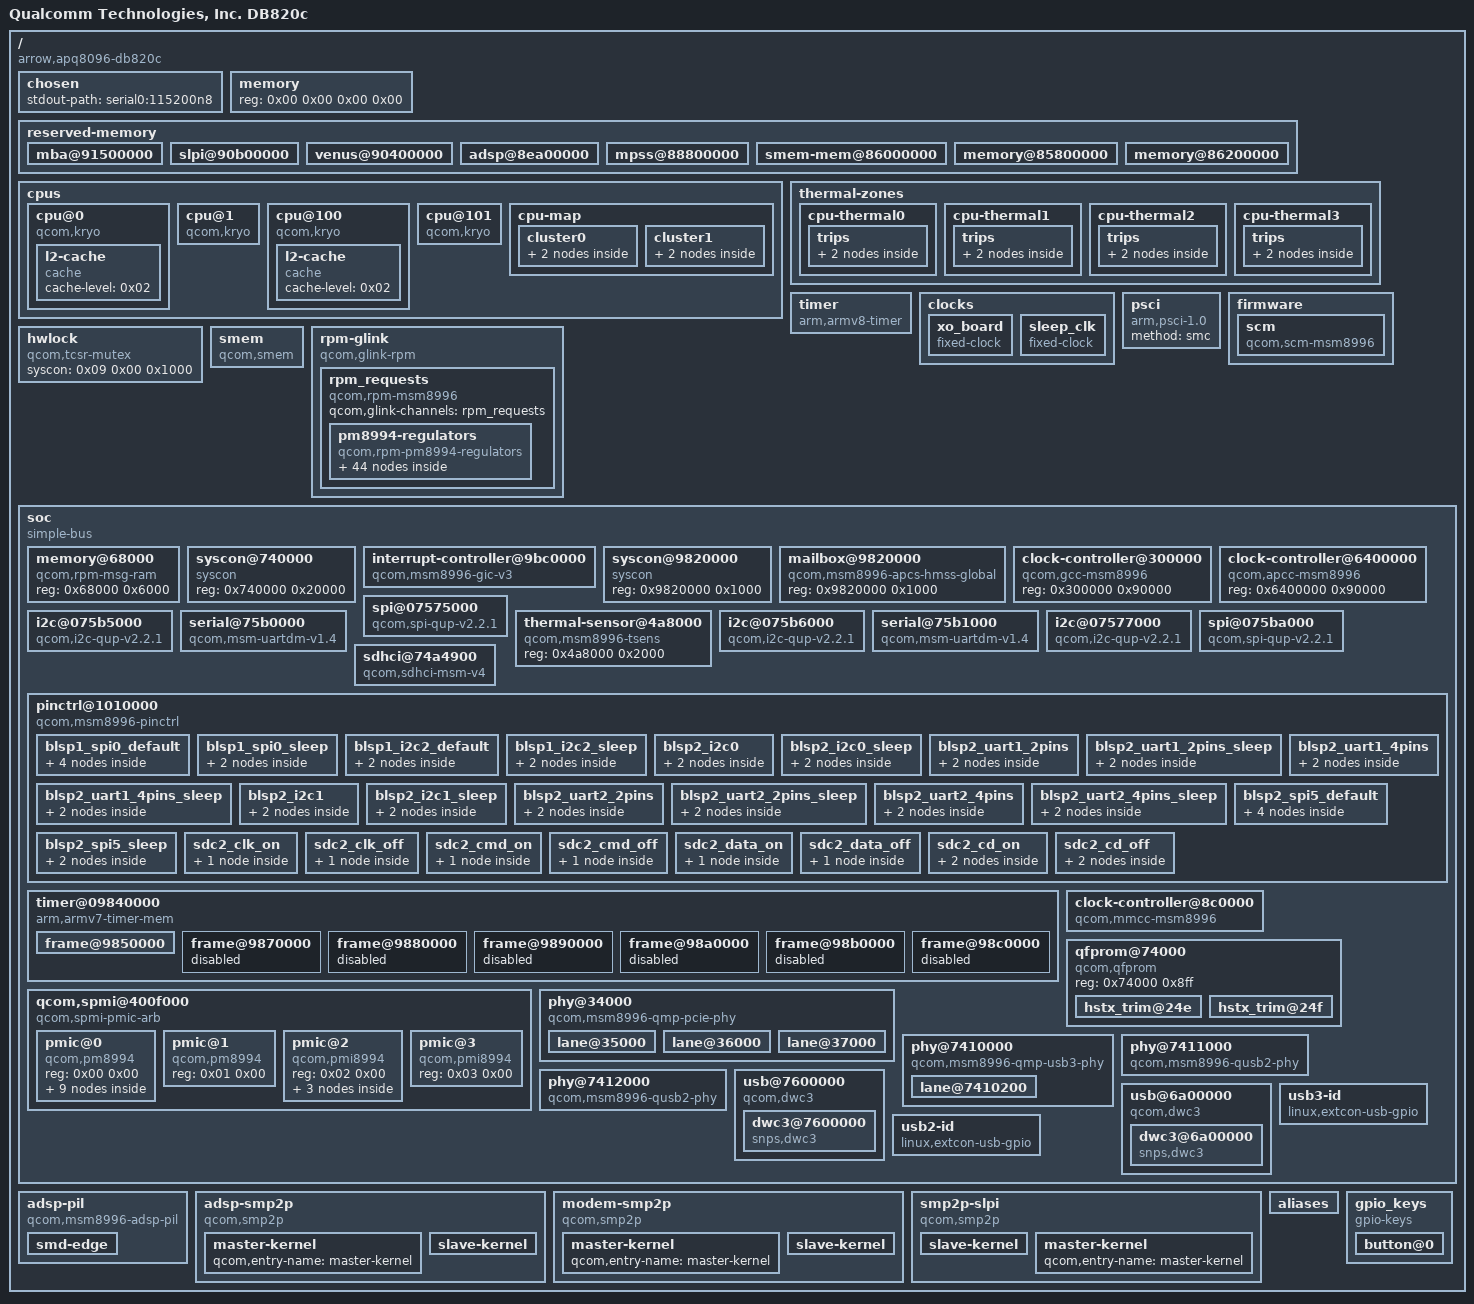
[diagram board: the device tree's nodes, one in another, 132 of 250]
/dts-v1/;

/ {
	model = "Qualcomm Technologies, Inc. DB820c";
	interrupt-parent = <0x01>;
	#address-cells = <0x02>;
	#size-cells = <0x02>;
	compatible = "arrow,apq8096-db820c\0qcom,apq8096-sbc";

	chosen {
		stdout-path = "serial0:115200n8";
	};

	memory {
		device_type = "memory";
		reg = <0x00 0x00 0x00 0x00>;
	};

	reserved-memory {
		#address-cells = <0x02>;
		#size-cells = <0x02>;
		ranges;

		mba@91500000 {
			reg = <0x00 0x91500000 0x00 0x200000>;
			no-map;
			phandle = <0x3e>;
		};

		slpi@90b00000 {
			reg = <0x00 0x90b00000 0x00 0xa00000>;
			no-map;
			phandle = <0x3f>;
		};

		venus@90400000 {
			reg = <0x00 0x90400000 0x00 0x700000>;
			no-map;
			phandle = <0x40>;
		};

		adsp@8ea00000 {
			reg = <0x00 0x8ea00000 0x00 0x1a00000>;
			no-map;
			phandle = <0x3a>;
		};

		mpss@88800000 {
			reg = <0x00 0x88800000 0x00 0x6200000>;
			no-map;
			phandle = <0x41>;
		};

		smem-mem@86000000 {
			reg = <0x00 0x86000000 0x00 0x200000>;
			no-map;
			phandle = <0x0a>;
		};

		memory@85800000 {
			reg = <0x00 0x85800000 0x00 0x800000>;
			no-map;
		};

		memory@86200000 {
			reg = <0x00 0x86200000 0x00 0x2600000>;
			no-map;
		};
	};

	cpus {
		#address-cells = <0x02>;
		#size-cells = <0x00>;

		cpu@0 {
			device_type = "cpu";
			compatible = "qcom,kryo";
			reg = <0x00 0x00>;
			enable-method = "psci";
			next-level-cache = <0x02>;
			phandle = <0x04>;

			l2-cache {
				compatible = "cache";
				cache-level = <0x02>;
				phandle = <0x02>;
			};
		};

		cpu@1 {
			device_type = "cpu";
			compatible = "qcom,kryo";
			reg = <0x00 0x01>;
			enable-method = "psci";
			next-level-cache = <0x02>;
			phandle = <0x05>;
		};

		cpu@100 {
			device_type = "cpu";
			compatible = "qcom,kryo";
			reg = <0x00 0x100>;
			enable-method = "psci";
			next-level-cache = <0x03>;
			phandle = <0x06>;

			l2-cache {
				compatible = "cache";
				cache-level = <0x02>;
				phandle = <0x03>;
			};
		};

		cpu@101 {
			device_type = "cpu";
			compatible = "qcom,kryo";
			reg = <0x00 0x101>;
			enable-method = "psci";
			next-level-cache = <0x03>;
			phandle = <0x07>;
		};

		cpu-map {

			cluster0 {

				core0 {
					cpu = <0x04>;
				};

				core1 {
					cpu = <0x05>;
				};
			};

			cluster1 {

				core0 {
					cpu = <0x06>;
				};

				core1 {
					cpu = <0x07>;
				};
			};
		};
	};

	thermal-zones {

		cpu-thermal0 {
			polling-delay-passive = <0xfa>;
			polling-delay = <0x3e8>;
			thermal-sensors = <0x08 0x03>;

			trips {

				trip0 {
					temperature = <0x124f8>;
					hysteresis = <0x7d0>;
					type = "passive";
					phandle = <0x42>;
				};

				trip1 {
					temperature = <0x1adb0>;
					hysteresis = <0x7d0>;
					type = "critical";
					phandle = <0x43>;
				};
			};
		};

		cpu-thermal1 {
			polling-delay-passive = <0xfa>;
			polling-delay = <0x3e8>;
			thermal-sensors = <0x08 0x05>;

			trips {

				trip0 {
					temperature = <0x124f8>;
					hysteresis = <0x7d0>;
					type = "passive";
					phandle = <0x44>;
				};

				trip1 {
					temperature = <0x1adb0>;
					hysteresis = <0x7d0>;
					type = "critical";
					phandle = <0x45>;
				};
			};
		};

		cpu-thermal2 {
			polling-delay-passive = <0xfa>;
			polling-delay = <0x3e8>;
			thermal-sensors = <0x08 0x08>;

			trips {

				trip0 {
					temperature = <0x124f8>;
					hysteresis = <0x7d0>;
					type = "passive";
					phandle = <0x46>;
				};

				trip1 {
					temperature = <0x1adb0>;
					hysteresis = <0x7d0>;
					type = "critical";
					phandle = <0x47>;
				};
			};
		};

		cpu-thermal3 {
			polling-delay-passive = <0xfa>;
			polling-delay = <0x3e8>;
			thermal-sensors = <0x08 0x0a>;

			trips {

				trip0 {
					temperature = <0x124f8>;
					hysteresis = <0x7d0>;
					type = "passive";
					phandle = <0x48>;
				};

				trip1 {
					temperature = <0x1adb0>;
					hysteresis = <0x7d0>;
					type = "critical";
					phandle = <0x49>;
				};
			};
		};
	};

	timer {
		compatible = "arm,armv8-timer";
		interrupts = <0x01 0x0d 0xf08 0x01 0x0e 0xf08 0x01 0x0b 0xf08 0x01 0x0a 0xf08>;
	};

	clocks {

		xo_board {
			compatible = "fixed-clock";
			#clock-cells = <0x00>;
			clock-frequency = <0x124f800>;
			clock-output-names = "xo_board";
			phandle = <0x1f>;
		};

		sleep_clk {
			compatible = "fixed-clock";
			#clock-cells = <0x00>;
			clock-frequency = <0x7ffc>;
			clock-output-names = "sleep_clk";
			phandle = <0x4a>;
		};
	};

	psci {
		compatible = "arm,psci-1.0";
		method = "smc";
	};

	firmware {

		scm {
			compatible = "qcom,scm-msm8996";
		};
	};

	hwlock {
		compatible = "qcom,tcsr-mutex";
		syscon = <0x09 0x00 0x1000>;
		#hwlock-cells = <0x01>;
		phandle = <0x0b>;
	};

	smem {
		compatible = "qcom,smem";
		memory-region = <0x0a>;
		hwlocks = <0x0b 0x03>;
	};

	rpm-glink {
		compatible = "qcom,glink-rpm";
		interrupts = <0x00 0xa8 0x01>;
		qcom,rpm-msg-ram = <0x0c>;
		mboxes = <0x0d 0x00>;

		rpm_requests {
			compatible = "qcom,rpm-msm8996";
			qcom,glink-channels = "rpm_requests";

			pm8994-regulators {
				compatible = "qcom,rpm-pm8994-regulators";
				vdd_l1-supply = <0x0e>;
				vdd_l2_l26_l28-supply = <0x0e>;
				vdd_l3_l11-supply = <0x0e>;
				vdd_l4_l27_l31-supply = <0x0e>;
				vdd_l5_l7-supply = <0x0f>;
				vdd_l14_l15-supply = <0x0f>;
				vdd_l20_l21-supply = <0x0f>;
				vdd_l25-supply = <0x0e>;

				s1 {
					phandle = <0x4b>;
				};

				s2 {
					phandle = <0x4c>;
				};

				s3 {
					regulator-min-microvolt = <0x13d620>;
					regulator-max-microvolt = <0x13d620>;
					phandle = <0x0e>;
				};

				s4 {
					regulator-min-microvolt = <0x1b7740>;
					regulator-max-microvolt = <0x1b7740>;
					phandle = <0x4d>;
				};

				s5 {
					regulator-min-microvolt = <0x20ce70>;
					regulator-max-microvolt = <0x20ce70>;
					phandle = <0x0f>;
				};

				s6 {
					phandle = <0x4e>;
				};

				s7 {
					regulator-min-microvolt = <0xc3500>;
					regulator-max-microvolt = <0xc3500>;
					phandle = <0x4f>;
				};

				s8 {
					phandle = <0x50>;
				};

				s9 {
					phandle = <0x51>;
				};

				s10 {
					phandle = <0x52>;
				};

				s11 {
					phandle = <0x53>;
				};

				s12 {
					phandle = <0x54>;
				};

				l1 {
					regulator-min-microvolt = <0xf4240>;
					regulator-max-microvolt = <0xf4240>;
					phandle = <0x55>;
				};

				l2 {
					regulator-min-microvolt = <0x1312d0>;
					regulator-max-microvolt = <0x1312d0>;
					phandle = <0x56>;
				};

				l3 {
					regulator-min-microvolt = <0xcf850>;
					regulator-max-microvolt = <0xcf850>;
					phandle = <0x57>;
				};

				l4 {
					regulator-min-microvolt = <0x12b128>;
					regulator-max-microvolt = <0x12b128>;
					phandle = <0x58>;
				};

				l5 {
					phandle = <0x59>;
				};

				l6 {
					regulator-min-microvolt = <0x124f80>;
					regulator-max-microvolt = <0x124f80>;
					phandle = <0x5a>;
				};

				l7 {
					phandle = <0x5b>;
				};

				l8 {
					regulator-min-microvolt = <0x1b7740>;
					regulator-max-microvolt = <0x1b7740>;
					phandle = <0x5c>;
				};

				l9 {
					regulator-min-microvolt = <0x1b7740>;
					regulator-max-microvolt = <0x1b7740>;
					phandle = <0x5d>;
				};

				l10 {
					regulator-min-microvolt = <0x1b7740>;
					regulator-max-microvolt = <0x1b7740>;
					phandle = <0x5e>;
				};

				l11 {
					regulator-min-microvolt = <0x118c30>;
					regulator-max-microvolt = <0x118c30>;
					phandle = <0x5f>;
				};

				l12 {
					regulator-min-microvolt = <0x1b7740>;
					regulator-max-microvolt = <0x1b7740>;
					phandle = <0x2c>;
				};

				l13 {
					regulator-min-microvolt = <0x1b7740>;
					regulator-max-microvolt = <0x2d0370>;
					phandle = <0x60>;
				};

				l14 {
					regulator-min-microvolt = <0x1b7740>;
					regulator-max-microvolt = <0x1b7740>;
					phandle = <0x61>;
				};

				l15 {
					regulator-min-microvolt = <0x1b7740>;
					regulator-max-microvolt = <0x1b7740>;
					phandle = <0x62>;
				};

				l16 {
					regulator-min-microvolt = <0x2932e0>;
					regulator-max-microvolt = <0x2932e0>;
					phandle = <0x63>;
				};

				l17 {
					regulator-min-microvolt = <0x2625a0>;
					regulator-max-microvolt = <0x2625a0>;
					phandle = <0x64>;
				};

				l18 {
					regulator-min-microvolt = <0x2932e0>;
					regulator-max-microvolt = <0x2c4020>;
					phandle = <0x65>;
				};

				l19 {
					regulator-min-microvolt = <0x2dc6c0>;
					regulator-max-microvolt = <0x2dc6c0>;
					phandle = <0x66>;
				};

				l20 {
					regulator-min-microvolt = <0x2d0370>;
					regulator-max-microvolt = <0x2d0370>;
					regulator-allow-set-load;
					phandle = <0x67>;
				};

				l21 {
					regulator-min-microvolt = <0x2d0370>;
					regulator-max-microvolt = <0x2d0370>;
					phandle = <0x68>;
				};

				l22 {
					regulator-min-microvolt = <0x325aa0>;
					regulator-max-microvolt = <0x325aa0>;
					phandle = <0x69>;
				};

				l23 {
					regulator-min-microvolt = <0x2ab980>;
					regulator-max-microvolt = <0x2ab980>;
					phandle = <0x6a>;
				};

				l24 {
					regulator-min-microvolt = <0x2eebb8>;
					regulator-max-microvolt = <0x2eebb8>;
					phandle = <0x2d>;
				};

				l25 {
					regulator-min-microvolt = <0x124f80>;
					regulator-max-microvolt = <0x124f80>;
					regulator-allow-set-load;
					phandle = <0x6b>;
				};

				l26 {
					phandle = <0x6c>;
				};

				l27 {
					regulator-min-microvolt = <0xf4240>;
					regulator-max-microvolt = <0xf4240>;
					phandle = <0x6d>;
				};

				l28 {
					regulator-min-microvolt = <0xe1d48>;
					regulator-max-microvolt = <0xe1d48>;
					regulator-allow-set-load;
					phandle = <0x2b>;
				};

				l29 {
					regulator-min-microvolt = <0x2ab980>;
					regulator-max-microvolt = <0x2ab980>;
					phandle = <0x6e>;
				};

				l30 {
					regulator-min-microvolt = <0x1b7740>;
					regulator-max-microvolt = <0x1b7740>;
					phandle = <0x6f>;
				};

				l31 {
					phandle = <0x70>;
				};

				l32 {
					regulator-min-microvolt = <0x1b7740>;
					regulator-max-microvolt = <0x1b7740>;
					phandle = <0x71>;
				};
			};
		};
	};

	soc {
		#address-cells = <0x01>;
		#size-cells = <0x01>;
		ranges = <0x00 0x00 0x00 0xffffffff>;
		compatible = "simple-bus";
		phandle = <0x72>;

		memory@68000 {
			compatible = "qcom,rpm-msg-ram";
			reg = <0x68000 0x6000>;
			phandle = <0x0c>;
		};

		syscon@740000 {
			compatible = "syscon";
			reg = <0x740000 0x20000>;
			phandle = <0x09>;
		};

		interrupt-controller@9bc0000 {
			compatible = "qcom,msm8996-gic-v3\0arm,gic-v3";
			#interrupt-cells = <0x03>;
			interrupt-controller;
			#redistributor-regions = <0x01>;
			redistributor-stride = <0x00 0x40000>;
			reg = <0x9bc0000 0x10000 0x9c00000 0x100000>;
			interrupts = <0x01 0x09 0x04>;
			phandle = <0x01>;
		};

		syscon@9820000 {
			compatible = "syscon";
			reg = <0x9820000 0x1000>;
			phandle = <0x3c>;
		};

		mailbox@9820000 {
			compatible = "qcom,msm8996-apcs-hmss-global";
			reg = <0x9820000 0x1000>;
			#mbox-cells = <0x01>;
			phandle = <0x0d>;
		};

		clock-controller@300000 {
			compatible = "qcom,gcc-msm8996";
			#clock-cells = <0x01>;
			#reset-cells = <0x01>;
			#power-domain-cells = <0x01>;
			reg = <0x300000 0x90000>;
			phandle = <0x10>;
		};

		clock-controller@6400000 {
			compatible = "qcom,apcc-msm8996";
			reg = <0x6400000 0x90000>;
			#clock-cells = <0x01>;
			phandle = <0x73>;
		};

		spi@07575000 {
			compatible = "qcom,spi-qup-v2.2.1";
			reg = <0x7575000 0x600>;
			interrupts = <0x00 0x5f 0x04>;
			clocks = <0x10 0x6f 0x10 0x6d>;
			clock-names = "core\0iface";
			pinctrl-names = "default\0sleep";
			pinctrl-0 = <0x11>;
			pinctrl-1 = <0x12>;
			#address-cells = <0x01>;
			#size-cells = <0x00>;
			status = "okay";
			label = "LS-SPI0";
			phandle = <0x74>;
		};

		i2c@075b5000 {
			compatible = "qcom,i2c-qup-v2.2.1";
			reg = <0x75b5000 0x1000>;
			interrupts = <0x00 0x65 0x00>;
			clocks = <0x10 0x81 0x10 0x84>;
			clock-names = "iface\0core";
			pinctrl-names = "default\0sleep";
			pinctrl-0 = <0x13>;
			pinctrl-1 = <0x14>;
			#address-cells = <0x01>;
			#size-cells = <0x00>;
			status = "okay";
			label = "HS-I2C2";
			phandle = <0x75>;
		};

		thermal-sensor@4a8000 {
			compatible = "qcom,msm8996-tsens";
			reg = <0x4a8000 0x2000>;
			#thermal-sensor-cells = <0x01>;
			phandle = <0x08>;
		};

		serial@75b0000 {
			compatible = "qcom,msm-uartdm-v1.4\0qcom,msm-uartdm";
			reg = <0x75b0000 0x1000>;
			interrupts = <0x00 0x72 0x04>;
			clocks = <0x10 0x88 0x10 0x81>;
			clock-names = "core\0iface";
			status = "okay";
			label = "LS-UART1";
			pinctrl-names = "default\0sleep";
			pinctrl-0 = <0x15>;
			pinctrl-1 = <0x16>;
			phandle = <0x76>;
		};

		i2c@075b6000 {
			compatible = "qcom,i2c-qup-v2.2.1";
			reg = <0x75b6000 0x1000>;
			interrupts = <0x00 0x66 0x00>;
			clocks = <0x10 0x81 0x10 0x87>;
			clock-names = "iface\0core";
			pinctrl-names = "default\0sleep";
			pinctrl-0 = <0x17>;
			pinctrl-1 = <0x18>;
			#address-cells = <0x01>;
			#size-cells = <0x00>;
			status = "okay";
			label = "LS-I2C1";
			phandle = <0x77>;
		};

		serial@75b1000 {
			compatible = "qcom,msm-uartdm-v1.4\0qcom,msm-uartdm";
			reg = <0x75b1000 0x1000>;
			interrupts = <0x00 0x73 0x04>;
			clocks = <0x10 0x8b 0x10 0x81>;
			clock-names = "core\0iface";
			status = "okay";
			label = "LS-UART0";
			pinctrl-names = "default\0sleep";
			pinctrl-0 = <0x19>;
			pinctrl-1 = <0x1a>;
			phandle = <0x78>;
		};

		i2c@07577000 {
			compatible = "qcom,i2c-qup-v2.2.1";
			reg = <0x7577000 0x1000>;
			interrupts = <0x00 0x61 0x00>;
			clocks = <0x10 0x6d 0x10 0x76>;
			clock-names = "iface\0core";
			pinctrl-names = "default\0sleep";
			pinctrl-0 = <0x1b>;
			pinctrl-1 = <0x1c>;
			#address-cells = <0x01>;
			#size-cells = <0x00>;
			status = "okay";
			label = "LS-I2C0";
			phandle = <0x79>;
		};

		spi@075ba000 {
			compatible = "qcom,spi-qup-v2.2.1";
			reg = <0x75ba000 0x600>;
			interrupts = <0x00 0x6a 0x04>;
			clocks = <0x10 0x92 0x10 0x81>;
			clock-names = "core\0iface";
			pinctrl-names = "default\0sleep";
			pinctrl-0 = <0x1d>;
			pinctrl-1 = <0x1e>;
			#address-cells = <0x01>;
			#size-cells = <0x00>;
			status = "okay";
			label = "HS-SPI1";
			phandle = <0x7a>;
		};

		sdhci@74a4900 {
			status = "okay";
			compatible = "qcom,sdhci-msm-v4";
			reg = <0x74a4900 0x314 0x74a4000 0x800>;
			reg-names = "hc_mem\0core_mem";
			interrupts = <0x00 0x7d 0x00 0x00 0xdd 0x00>;
			interrupt-names = "hc_irq\0pwr_irq";
			clock-names = "iface\0core\0xo";
			clocks = <0x10 0x68 0x10 0x67 0x1f>;
			bus-width = <0x04>;
			pinctrl-names = "default\0sleep";
			pinctrl-0 = <0x20 0x21 0x22 0x23>;
			pinctrl-1 = <0x24 0x25 0x26 0x27>;
			cd-gpios = <0x28 0x26 0x01>;
			phandle = <0x7b>;
		};

		pinctrl@1010000 {
			compatible = "qcom,msm8996-pinctrl";
			reg = <0x1010000 0x300000>;
			interrupts = <0x00 0xd0 0x04>;
			gpio-controller;
			#gpio-cells = <0x02>;
			interrupt-controller;
			#interrupt-cells = <0x02>;
			phandle = <0x28>;

			blsp1_spi0_default {
				phandle = <0x11>;

				pinmux {
					function = "blsp_spi1";
					pins = "gpio0\0gpio1\0gpio3";
				};

				pinmux_cs {
					function = "gpio";
					pins = "gpio2";
				};

				pinconf {
					pins = "gpio0\0gpio1\0gpio3";
					drive-strength = <0x0c>;
					bias-disable;
				};

				pinconf_cs {
					pins = "gpio2";
					drive-strength = <0x10>;
					bias-disable;
					output-high;
				};
			};

			blsp1_spi0_sleep {
				phandle = <0x12>;

				pinmux {
					function = "gpio";
					pins = "gpio0\0gpio1\0gpio2\0gpio3";
				};

				pinconf {
					pins = "gpio0\0gpio1\0gpio2\0gpio3";
					drive-strength = <0x02>;
					bias-pull-down;
				};
			};

			blsp1_i2c2_default {
				phandle = <0x1b>;

				pinmux {
					function = "blsp_i2c3";
					pins = "gpio47\0gpio48";
				};

				pinconf {
					pins = "gpio47\0gpio48";
					drive-strength = <0x10>;
					bias-disable = <0x00>;
				};
			};

			blsp1_i2c2_sleep {
				phandle = <0x1c>;

				pinmux {
					function = "gpio";
					pins = "gpio47\0gpio48";
				};

				pinconf {
					pins = "gpio47\0gpio48";
					drive-strength = <0x02>;
					bias-disable = <0x00>;
				};
			};

			blsp2_i2c0 {
				phandle = <0x13>;

				pinmux {
					function = "blsp_i2c7";
					pins = "gpio55\0gpio56";
				};

				pinconf {
					pins = "gpio55\0gpio56";
					drive-strength = <0x10>;
					bias-disable;
				};
			};

			blsp2_i2c0_sleep {
				phandle = <0x14>;

				pinmux {
					function = "gpio";
					pins = "gpio55\0gpio56";
				};

				pinconf {
					pins = "gpio55\0gpio56";
					drive-strength = <0x02>;
					bias-disable;
				};
			};

			blsp2_uart1_2pins {
				phandle = <0x15>;

				pinmux {
					function = "blsp_uart8";
					pins = "gpio4\0gpio5";
				};

				pinconf {
					pins = "gpio4\0gpio5";
					drive-strength = <0x10>;
					bias-disable;
				};
			};

			blsp2_uart1_2pins_sleep {
				phandle = <0x16>;

				pinmux {
					function = "gpio";
					pins = "gpio4\0gpio5";
				};

				pinconf {
					pins = "gpio4\0gpio5";
					drive-strength = <0x02>;
					bias-disable;
				};
			};

			blsp2_uart1_4pins {
				phandle = <0x7c>;

				pinmux {
					function = "blsp_uart8";
					pins = "gpio4\0gpio5\0gpio6\0gpio7";
				};

				pinconf {
					pins = "gpio4\0gpio5\0gpio6\0gpio7";
					drive-strength = <0x10>;
					bias-disable;
				};
			};

			blsp2_uart1_4pins_sleep {
				phandle = <0x7d>;

				pinmux {
					function = "gpio";
					pins = "gpio4\0gpio5\0gpio6\0gpio7";
				};

				pinconf {
					pins = "gpio4\0gpiio5\0gpio6\0gpio7";
					drive-strength = <0x02>;
					bias-disable;
				};
			};

			blsp2_i2c1 {
				phandle = <0x17>;

				pinmux {
					function = "blsp_i2c8";
					pins = "gpio6\0gpio7";
				};

				pinconf {
					pins = "gpio6\0gpio7";
					drive-strength = <0x10>;
					bias-disable;
				};
			};

			blsp2_i2c1_sleep {
				phandle = <0x18>;

				pinmux {
					function = "gpio";
					pins = "gpio6\0gpio7";
				};

				pinconf {
					pins = "gpio6\0gpio7";
					drive-strength = <0x02>;
					bias-disable;
				};
			};

			blsp2_uart2_2pins {
				phandle = <0x7e>;

				pinmux {
					function = "blsp_uart9";
					pins = "gpio49\0gpio50";
				};

				pinconf {
					pins = "gpio49\0gpio50";
					drive-strength = <0x10>;
					bias-disable;
				};
			};

			blsp2_uart2_2pins_sleep {
				phandle = <0x7f>;

				pinmux {
					function = "gpio";
					pins = "gpio49\0gpio50";
				};

				pinconf {
					pins = "gpio49\0gpio50";
					drive-strength = <0x02>;
					bias-disable;
				};
			};

			blsp2_uart2_4pins {
				phandle = <0x19>;

				pinmux {
					function = "blsp_uart9";
					pins = "gpio49\0gpio50\0gpio51\0gpio52";
				};

				pinconf {
					pins = "gpio49\0gpio50\0gpio51\0gpio52";
					drive-strength = <0x10>;
					bias-disable;
				};
			};

			blsp2_uart2_4pins_sleep {
				phandle = <0x1a>;

				pinmux {
					function = "gpio";
					pins = "gpio49\0gpio50\0gpio51\0gpio52";
				};

				pinconf {
					pins = "gpio49\0gpio50\0gpio51\0gpio52";
					drive-strength = <0x02>;
					bias-disable;
				};
			};

			blsp2_spi5_default {
				phandle = <0x1d>;

				pinmux {
					function = "blsp_spi12";
					pins = "gpio85\0gpio86\0gpio88";
				};

				pinmux_cs {
					function = "gpio";
					pins = "gpio87";
				};

				pinconf {
					pins = "gpio85\0gpio86\0gpio88";
					drive-strength = <0x0c>;
					bias-disable;
				};

				pinconf_cs {
					pins = "gpio87";
					drive-strength = <0x10>;
					bias-disable;
					output-high;
				};
			};

			blsp2_spi5_sleep {
				phandle = <0x1e>;

				pinmux {
					function = "gpio";
					pins = "gpio85\0gpio86\0gpio87\0gpio88";
				};

				pinconf {
					pins = "gpio85\0gpio86\0gpio87\0gpio88";
					drive-strength = <0x02>;
					bias-pull-down;
				};
			};

			sdc2_clk_on {
				phandle = <0x20>;

				config {
					pins = "sdc2_clk";
					bias-disable;
					drive-strength = <0x10>;
				};
			};

			sdc2_clk_off {
				phandle = <0x24>;

				config {
					pins = "sdc2_clk";
					bias-disable;
					drive-strength = <0x02>;
				};
			};

			sdc2_cmd_on {
				phandle = <0x21>;

				config {
					pins = "sdc2_cmd";
					bias-pull-up;
					drive-strength = <0x0a>;
				};
			};

			sdc2_cmd_off {
				phandle = <0x25>;

				config {
					pins = "sdc2_cmd";
					bias-pull-up;
					drive-strength = <0x02>;
				};
			};

			sdc2_data_on {
				phandle = <0x22>;

				config {
					pins = "sdc2_data";
					bias-pull-up;
					drive-strength = <0x0a>;
				};
			};

			sdc2_data_off {
				phandle = <0x26>;

				config {
					pins = "sdc2_data";
					bias-pull-up;
					drive-strength = <0x02>;
				};
			};

			sdc2_cd_on {
				phandle = <0x23>;

				mux {
					pins = "gpio38";
					function = "gpio";
				};

				config {
					pins = "gpio38";
					bias-pull-up;
					drive-strength = <0x10>;
				};
			};

			sdc2_cd_off {
				phandle = <0x27>;

				mux {
					pins = "gpio38";
					function = "gpio";
				};

				config {
					pins = "gpio38";
					bias-pull-up;
					drive-strength = <0x02>;
				};
			};
		};

		timer@09840000 {
			#address-cells = <0x01>;
			#size-cells = <0x01>;
			ranges;
			compatible = "arm,armv7-timer-mem";
			reg = <0x9840000 0x1000>;
			clock-frequency = <0x124f800>;

			frame@9850000 {
				frame-number = <0x00>;
				interrupts = <0x00 0x1f 0x04 0x00 0x1e 0x04>;
				reg = <0x9850000 0x1000 0x9860000 0x1000>;
			};

			frame@9870000 {
				frame-number = <0x01>;
				interrupts = <0x00 0x20 0x04>;
				reg = <0x9870000 0x1000>;
				status = "disabled";
			};

			frame@9880000 {
				frame-number = <0x02>;
				interrupts = <0x00 0x21 0x04>;
				reg = <0x9880000 0x1000>;
				status = "disabled";
			};

			frame@9890000 {
				frame-number = <0x03>;
				interrupts = <0x00 0x22 0x04>;
				reg = <0x9890000 0x1000>;
				status = "disabled";
			};

			frame@98a0000 {
				frame-number = <0x04>;
				interrupts = <0x00 0x23 0x04>;
				reg = <0x98a0000 0x1000>;
				status = "disabled";
			};

			frame@98b0000 {
				frame-number = <0x05>;
				interrupts = <0x00 0x24 0x04>;
				reg = <0x98b0000 0x1000>;
				status = "disabled";
			};

			frame@98c0000 {
				frame-number = <0x06>;
				interrupts = <0x00 0x25 0x04>;
				reg = <0x98c0000 0x1000>;
				status = "disabled";
			};
		};

		qcom,spmi@400f000 {
			compatible = "qcom,spmi-pmic-arb";
			reg = <0x400f000 0x1000 0x4400000 0x800000 0x4c00000 0x800000 0x5800000 0x200000 0x400a000 0x2100>;
			reg-names = "core\0chnls\0obsrvr\0intr\0cnfg";
			interrupt-names = "periph_irq";
			interrupts = <0x00 0x146 0x04>;
			qcom,ee = <0x00>;
			qcom,channel = <0x00>;
			#address-cells = <0x02>;
			#size-cells = <0x00>;
			interrupt-controller;
			#interrupt-cells = <0x04>;
			phandle = <0x80>;

			pmic@0 {
				compatible = "qcom,pm8994\0qcom,spmi-pmic";
				reg = <0x00 0x00>;
				#address-cells = <0x01>;
				#size-cells = <0x00>;

				rtc@6000 {
					compatible = "qcom,pm8941-rtc";
					reg = <0x6000 0x6100>;
					reg-names = "rtc\0alarm";
					interrupts = <0x00 0x61 0x01 0x01>;
				};

				gpios@c000 {
					compatible = "qcom,pm8994-gpio";
					reg = <0xc000>;
					gpio-controller;
					#gpio-cells = <0x02>;
					interrupts = <0x00 0xc0 0x00 0x00 0x00 0xc1 0x00 0x00 0x00 0xc2 0x00 0x00 0x00 0xc3 0x00 0x00 0x00 0xc4 0x00 0x00 0x00 0xc5 0x00 0x00 0x00 0xc6 0x00 0x00 0x00 0xc7 0x00 0x00 0x00 0xc8 0x00 0x00 0x00 0xc9 0x00 0x00 0x00 0xca 0x00 0x00 0x00 0xcb 0x00 0x00 0x00 0xcc 0x00 0x00 0x00 0xcd 0x00 0x00 0x00 0xce 0x00 0x00 0x00 0xcf 0x00 0x00 0x00 0xd0 0x00 0x00 0x00 0xd1 0x00 0x00 0x00 0xd2 0x00 0x00 0x00 0xd3 0x00 0x00 0x00 0xd4 0x00 0x00 0x00 0xd5 0x00 0x00>;
					pinctrl-names = "default";
					pinctrl-0 = <0x29>;
					phandle = <0x35>;

					pm8994_gpio5 {
						phandle = <0x29>;

						pinconf {
							pins = "gpio5";
							output-low;
							power-source = <0x02>;
						};
					};

					pm8996_gpio2 {
						phandle = <0x3d>;

						pinconf {
							pins = "gpio2";
							function = "normal";
							input-enable;
							drive-push-pull;
							bias-pull-up;
							qcom,drive-strength = <0x00>;
							power-source = <0x02>;
						};
					};

					pm8996_gpio22 {
						phandle = <0x36>;

						pinconf {
							pins = "gpio22";
							function = "normal";
							input-enable;
							bias-pull-down;
							qcom,drive-strength = <0x00>;
							power-source = <0x02>;
						};
					};
				};

				mpps@a000 {
					compatible = "qcom,pm8994-mpp";
					reg = <0xa000>;
					gpio-controller;
					#gpio-cells = <0x02>;
					interrupts = <0x00 0xa0 0x00 0x00 0x00 0xa1 0x00 0x00 0x00 0xa2 0x00 0x00 0x00 0xa3 0x00 0x00 0x00 0xa4 0x00 0x00 0x00 0xa5 0x00 0x00 0x00 0xa6 0x00 0x00 0x00 0xa7 0x00 0x00>;
					phandle = <0x81>;
				};
			};

			pmic@1 {
				compatible = "qcom,pm8994\0qcom,spmi-pmic";
				reg = <0x01 0x00>;
				#address-cells = <0x01>;
				#size-cells = <0x00>;
			};

			pmic@2 {
				compatible = "qcom,pmi8994\0qcom,spmi-pmic";
				reg = <0x02 0x00>;
				#address-cells = <0x01>;
				#size-cells = <0x00>;

				gpios@c000 {
					compatible = "qcom,pmi8994-gpio\0qcom,spmi-gpio";
					reg = <0xc000>;
					gpio-controller;
					#gpio-cells = <0x02>;
					interrupts = <0x02 0xc0 0x00 0x00 0x02 0xc1 0x00 0x00 0x02 0xc2 0x00 0x00 0x02 0xc3 0x00 0x00 0x02 0xc4 0x00 0x00 0x02 0xc5 0x00 0x00 0x02 0xc6 0x00 0x00 0x02 0xc7 0x00 0x00 0x02 0xc8 0x00 0x00 0x02 0xc9 0x00 0x00>;
					phandle = <0x37>;

					pmi8996_gpio6 {
						phandle = <0x38>;

						pinconf {
							pins = "gpio6";
							function = "normal";
							input-enable;
							bias-pull-down;
							qcom,drive-strength = <0x00>;
							power-source = <0x02>;
						};
					};
				};
			};

			pmic@3 {
				compatible = "qcom,pmi8994\0qcom,spmi-pmic";
				reg = <0x03 0x00>;
				#address-cells = <0x01>;
				#size-cells = <0x00>;
			};
		};

		clock-controller@8c0000 {
			compatible = "qcom,mmcc-msm8996";
			#clock-cells = <0x01>;
			#reset-cells = <0x01>;
			#power-domain-cells = <0x01>;
			reg = <0x8c0000 0x40000>;
			assigned-clocks = <0x2a 0x0f 0x2a 0x03 0x2a 0x07 0x2a 0x09 0x2a 0x0b>;
			assigned-clock-rates = <0x25317c00 0x30479e80 0x3a699d00 0x39387000 0x312c8040>;
			phandle = <0x2a>;
		};

		qfprom@74000 {
			compatible = "qcom,qfprom";
			reg = <0x74000 0x8ff>;
			#address-cells = <0x01>;
			#size-cells = <0x01>;

			hstx_trim@24e {
				reg = <0x24e 0x02>;
				bits = <0x05 0x04>;
				phandle = <0x2e>;
			};

			hstx_trim@24f {
				reg = <0x24f 0x01>;
				bits = <0x01 0x04>;
				phandle = <0x2f>;
			};
		};

		phy@34000 {
			compatible = "qcom,msm8996-qmp-pcie-phy";
			reg = <0x34000 0x488>;
			#clock-cells = <0x01>;
			#address-cells = <0x01>;
			#size-cells = <0x01>;
			ranges;
			clocks = <0x10 0xc0 0x10 0xbf 0x10 0xd8>;
			clock-names = "aux\0cfg_ahb\0ref";
			vdda-phy-supply = <0x2b>;
			vdda-pll-supply = <0x2c>;
			resets = <0x10 0x55 0x10 0x65 0x10 0x66>;
			reset-names = "phy\0common\0cfg";
			status = "okay";

			lane@35000 {
				reg = <0x35000 0x130 0x35200 0x200 0x35400 0x1dc>;
				#phy-cells = <0x00>;
				clock-output-names = "pcie_0_pipe_clk_src";
				clocks = <0x10 0xb4>;
				clock-names = "pipe0";
				resets = <0x10 0x50>;
				reset-names = "lane0";
				phandle = <0x82>;
			};

			lane@36000 {
				reg = <0x36000 0x130 0x36200 0x200 0x36400 0x1dc>;
				#phy-cells = <0x00>;
				clock-output-names = "pcie_1_pipe_clk_src";
				clocks = <0x10 0xb9>;
				clock-names = "pipe1";
				resets = <0x10 0x52>;
				reset-names = "lane1";
				phandle = <0x83>;
			};

			lane@37000 {
				reg = <0x37000 0x130 0x37200 0x200 0x37400 0x1dc>;
				#phy-cells = <0x00>;
				clock-output-names = "pcie_2_pipe_clk_src";
				clocks = <0x10 0xbe>;
				clock-names = "pipe2";
				resets = <0x10 0x54>;
				reset-names = "lane2";
				phandle = <0x84>;
			};
		};

		phy@7410000 {
			compatible = "qcom,msm8996-qmp-usb3-phy";
			reg = <0x7410000 0x1c4>;
			#clock-cells = <0x01>;
			#address-cells = <0x01>;
			#size-cells = <0x01>;
			ranges;
			clocks = <0x10 0x5e 0x10 0x63 0x10 0xd5>;
			clock-names = "aux\0cfg_ahb\0ref";
			vdda-phy-supply = <0x2b>;
			vdda-pll-supply = <0x2c>;
			resets = <0x10 0x67 0x10 0x68>;
			reset-names = "phy\0common";
			status = "okay";

			lane@7410200 {
				reg = <0x7410200 0x200 0x7410400 0x130 0x7410600 0x1a8>;
				#phy-cells = <0x00>;
				clock-output-names = "usb3_phy_pipe_clk_src";
				clocks = <0x10 0x5f>;
				clock-names = "pipe0";
				phandle = <0x33>;
			};
		};

		phy@7411000 {
			compatible = "qcom,msm8996-qusb2-phy";
			reg = <0x7411000 0x180>;
			#phy-cells = <0x00>;
			clocks = <0x10 0x63 0x10 0xda>;
			clock-names = "cfg_ahb\0ref";
			vdda-pll-supply = <0x2c>;
			vdda-phy-dpdm-supply = <0x2d>;
			resets = <0x10 0x09>;
			nvmem-cells = <0x2e>;
			status = "okay";
			phandle = <0x32>;
		};

		phy@7412000 {
			compatible = "qcom,msm8996-qusb2-phy";
			reg = <0x7412000 0x180>;
			#phy-cells = <0x00>;
			clocks = <0x10 0x63 0x10 0xd9>;
			clock-names = "cfg_ahb\0ref";
			vdda-pll-supply = <0x2c>;
			vdda-phy-dpdm-supply = <0x2d>;
			resets = <0x10 0x0a>;
			nvmem-cells = <0x2f>;
			status = "okay";
			phandle = <0x30>;
		};

		usb@7600000 {
			compatible = "qcom,dwc3";
			#address-cells = <0x01>;
			#size-cells = <0x01>;
			ranges;
			clocks = <0x10 0x55 0x10 0x60 0x10 0x62 0x10 0x61 0x10 0x63>;
			assigned-clocks = <0x10 0x62 0x10 0x60>;
			assigned-clock-rates = <0x124f800 0x3938700>;
			power-domains = <0x10 0x04>;
			status = "okay";
			phandle = <0x85>;

			dwc3@7600000 {
				compatible = "snps,dwc3";
				reg = <0x7600000 0xcc00>;
				interrupts = <0x00 0x8a 0x00>;
				phys = <0x30>;
				phy-names = "usb2-phy";
				extcon = <0x31>;
				dr_mode = "otg";
				maximum-speed = "high-speed";
			};
		};

		usb@6a00000 {
			compatible = "qcom,dwc3";
			#address-cells = <0x01>;
			#size-cells = <0x01>;
			ranges;
			clocks = <0x10 0x51 0x10 0x5b 0x10 0xd2 0x10 0x5d 0x10 0x5c 0x10 0x63>;
			assigned-clocks = <0x10 0x5d 0x10 0x5b>;
			assigned-clock-rates = <0x124f800 0x7270e00>;
			power-domains = <0x10 0x04>;
			status = "okay";
			phandle = <0x86>;

			dwc3@6a00000 {
				compatible = "snps,dwc3";
				reg = <0x6a00000 0xcc00>;
				interrupts = <0x00 0x83 0x00>;
				phys = <0x32 0x33>;
				phy-names = "usb2-phy\0usb3-phy";
				extcon = <0x34>;
				dr_mode = "otg";
			};
		};

		usb3-id {
			compatible = "linux,extcon-usb-gpio";
			id-gpio = <0x35 0x16 0x00>;
			pinctrl-names = "default";
			pinctrl-0 = <0x36>;
			phandle = <0x34>;
		};

		usb2-id {
			compatible = "linux,extcon-usb-gpio";
			id-gpio = <0x37 0x06 0x00>;
			pinctrl-names = "default";
			pinctrl-0 = <0x38>;
			phandle = <0x31>;
		};
	};

	adsp-pil {
		compatible = "qcom,msm8996-adsp-pil";
		interrupts-extended = <0x01 0x00 0xa2 0x01 0x39 0x00 0x01 0x39 0x01 0x01 0x39 0x02 0x01 0x39 0x03 0x01>;
		interrupt-names = "wdog\0fatal\0ready\0handover\0stop-ack";
		clocks = <0x1f>;
		clock-names = "xo";
		memory-region = <0x3a>;
		qcom,smem-states = <0x3b 0x00>;
		qcom,smem-state-names = "stop";

		smd-edge {
			interrupts = <0x00 0x9c 0x01>;
			label = "lpass";
			qcom,ipc = <0x3c 0x10 0x08>;
			qcom,smd-edge = <0x01>;
			qcom,remote-pid = <0x02>;
		};
	};

	adsp-smp2p {
		compatible = "qcom,smp2p";
		qcom,smem = <0x1bb 0x1ad>;
		interrupts = <0x00 0x9e 0x01>;
		qcom,ipc = <0x3c 0x10 0x0a>;
		qcom,local-pid = <0x00>;
		qcom,remote-pid = <0x02>;

		master-kernel {
			qcom,entry-name = "master-kernel";
			#qcom,smem-state-cells = <0x01>;
			phandle = <0x3b>;
		};

		slave-kernel {
			qcom,entry-name = "slave-kernel";
			interrupt-controller;
			#interrupt-cells = <0x02>;
			phandle = <0x39>;
		};
	};

	modem-smp2p {
		compatible = "qcom,smp2p";
		qcom,smem = <0x1b3 0x1ac>;
		interrupts = <0x00 0x1c3 0x01>;
		qcom,ipc = <0x3c 0x10 0x0e>;
		qcom,local-pid = <0x00>;
		qcom,remote-pid = <0x01>;

		master-kernel {
			qcom,entry-name = "master-kernel";
			#qcom,smem-state-cells = <0x01>;
			phandle = <0x87>;
		};

		slave-kernel {
			qcom,entry-name = "slave-kernel";
			interrupt-controller;
			#interrupt-cells = <0x02>;
			phandle = <0x88>;
		};
	};

	smp2p-slpi {
		compatible = "qcom,smp2p";
		qcom,smem = <0x1e1 0x1ae>;
		interrupts = <0x00 0xb2 0x01>;
		qcom,ipc = <0x3c 0x10 0x1a>;
		qcom,local-pid = <0x00>;
		qcom,remote-pid = <0x03>;

		slave-kernel {
			qcom,entry-name = "slave-kernel";
			interrupt-controller;
			#interrupt-cells = <0x02>;
			phandle = <0x89>;
		};

		master-kernel {
			qcom,entry-name = "master-kernel";
			#qcom,smem-state-cells = <0x01>;
			phandle = <0x8a>;
		};
	};

	aliases {
		serial0 = "/soc/serial@75b0000";
		serial1 = "/soc/serial@75b1000";
		i2c0 = "/soc/i2c@07577000";
		i2c1 = "/soc/i2c@075b6000";
		i2c2 = "/soc/i2c@075b5000";
		spi0 = "/soc/spi@07575000";
		spi1 = "/soc/spi@075ba000";
	};

	gpio_keys {
		compatible = "gpio-keys";
		#address-cells = <0x01>;
		#size-cells = <0x00>;
		autorepeat;
		pinctrl-names = "default";
		pinctrl-0 = <0x3d>;

		button@0 {
			label = "Volume Up";
			linux,code = <0x73>;
			gpios = <0x35 0x02 0x01>;
		};
	};

	__symbols__ {
		mba_region = "/reserved-memory/mba@91500000";
		slpi_region = "/reserved-memory/slpi@90b00000";
		venus_region = "/reserved-memory/venus@90400000";
		adsp_region = "/reserved-memory/adsp@8ea00000";
		mpss_region = "/reserved-memory/mpss@88800000";
		smem_mem = "/reserved-memory/smem-mem@86000000";
		CPU0 = "/cpus/cpu@0";
		L2_0 = "/cpus/cpu@0/l2-cache";
		CPU1 = "/cpus/cpu@1";
		CPU2 = "/cpus/cpu@100";
		L2_1 = "/cpus/cpu@100/l2-cache";
		CPU3 = "/cpus/cpu@101";
		cpu_alert0 = "/thermal-zones/cpu-thermal0/trips/trip0";
		cpu_crit0 = "/thermal-zones/cpu-thermal0/trips/trip1";
		cpu_alert1 = "/thermal-zones/cpu-thermal1/trips/trip0";
		cpu_crit1 = "/thermal-zones/cpu-thermal1/trips/trip1";
		cpu_alert2 = "/thermal-zones/cpu-thermal2/trips/trip0";
		cpu_crit2 = "/thermal-zones/cpu-thermal2/trips/trip1";
		cpu_alert3 = "/thermal-zones/cpu-thermal3/trips/trip0";
		cpu_crit3 = "/thermal-zones/cpu-thermal3/trips/trip1";
		xo_board = "/clocks/xo_board";
		sleep_clk = "/clocks/sleep_clk";
		tcsr_mutex = "/hwlock";
		pm8994_s1 = "/rpm-glink/rpm_requests/pm8994-regulators/s1";
		pm8994_s2 = "/rpm-glink/rpm_requests/pm8994-regulators/s2";
		pm8994_s3 = "/rpm-glink/rpm_requests/pm8994-regulators/s3";
		pm8994_s4 = "/rpm-glink/rpm_requests/pm8994-regulators/s4";
		pm8994_s5 = "/rpm-glink/rpm_requests/pm8994-regulators/s5";
		pm8994_s6 = "/rpm-glink/rpm_requests/pm8994-regulators/s6";
		pm8994_s7 = "/rpm-glink/rpm_requests/pm8994-regulators/s7";
		pm8994_s8 = "/rpm-glink/rpm_requests/pm8994-regulators/s8";
		pm8994_s9 = "/rpm-glink/rpm_requests/pm8994-regulators/s9";
		pm8994_s10 = "/rpm-glink/rpm_requests/pm8994-regulators/s10";
		pm8994_s11 = "/rpm-glink/rpm_requests/pm8994-regulators/s11";
		pm8994_s12 = "/rpm-glink/rpm_requests/pm8994-regulators/s12";
		pm8994_l1 = "/rpm-glink/rpm_requests/pm8994-regulators/l1";
		pm8994_l2 = "/rpm-glink/rpm_requests/pm8994-regulators/l2";
		pm8994_l3 = "/rpm-glink/rpm_requests/pm8994-regulators/l3";
		pm8994_l4 = "/rpm-glink/rpm_requests/pm8994-regulators/l4";
		pm8994_l5 = "/rpm-glink/rpm_requests/pm8994-regulators/l5";
		pm8994_l6 = "/rpm-glink/rpm_requests/pm8994-regulators/l6";
		pm8994_l7 = "/rpm-glink/rpm_requests/pm8994-regulators/l7";
		pm8994_l8 = "/rpm-glink/rpm_requests/pm8994-regulators/l8";
		pm8994_l9 = "/rpm-glink/rpm_requests/pm8994-regulators/l9";
		pm8994_l10 = "/rpm-glink/rpm_requests/pm8994-regulators/l10";
		pm8994_l11 = "/rpm-glink/rpm_requests/pm8994-regulators/l11";
		pm8994_l12 = "/rpm-glink/rpm_requests/pm8994-regulators/l12";
		pm8994_l13 = "/rpm-glink/rpm_requests/pm8994-regulators/l13";
		pm8994_l14 = "/rpm-glink/rpm_requests/pm8994-regulators/l14";
		pm8994_l15 = "/rpm-glink/rpm_requests/pm8994-regulators/l15";
		pm8994_l16 = "/rpm-glink/rpm_requests/pm8994-regulators/l16";
		pm8994_l17 = "/rpm-glink/rpm_requests/pm8994-regulators/l17";
		pm8994_l18 = "/rpm-glink/rpm_requests/pm8994-regulators/l18";
		pm8994_l19 = "/rpm-glink/rpm_requests/pm8994-regulators/l19";
		pm8994_l20 = "/rpm-glink/rpm_requests/pm8994-regulators/l20";
		pm8994_l21 = "/rpm-glink/rpm_requests/pm8994-regulators/l21";
		pm8994_l22 = "/rpm-glink/rpm_requests/pm8994-regulators/l22";
		pm8994_l23 = "/rpm-glink/rpm_requests/pm8994-regulators/l23";
		pm8994_l24 = "/rpm-glink/rpm_requests/pm8994-regulators/l24";
		pm8994_l25 = "/rpm-glink/rpm_requests/pm8994-regulators/l25";
		pm8994_l26 = "/rpm-glink/rpm_requests/pm8994-regulators/l26";
		pm8994_l27 = "/rpm-glink/rpm_requests/pm8994-regulators/l27";
		pm8994_l28 = "/rpm-glink/rpm_requests/pm8994-regulators/l28";
		pm8994_l29 = "/rpm-glink/rpm_requests/pm8994-regulators/l29";
		pm8994_l30 = "/rpm-glink/rpm_requests/pm8994-regulators/l30";
		pm8994_l31 = "/rpm-glink/rpm_requests/pm8994-regulators/l31";
		pm8994_l32 = "/rpm-glink/rpm_requests/pm8994-regulators/l32";
		soc = "/soc";
		rpm_msg_ram = "/soc/memory@68000";
		tcsr_mutex_regs = "/soc/syscon@740000";
		intc = "/soc/interrupt-controller@9bc0000";
		apcs = "/soc/syscon@9820000";
		apcs_glb = "/soc/mailbox@9820000";
		gcc = "/soc/clock-controller@300000";
		kryocc = "/soc/clock-controller@6400000";
		blsp1_spi0 = "/soc/spi@07575000";
		blsp2_i2c0 = "/soc/i2c@075b5000";
		tsens0 = "/soc/thermal-sensor@4a8000";
		blsp2_uart1 = "/soc/serial@75b0000";
		blsp2_i2c1 = "/soc/i2c@075b6000";
		blsp2_uart2 = "/soc/serial@75b1000";
		blsp1_i2c2 = "/soc/i2c@07577000";
		blsp2_spi5 = "/soc/spi@075ba000";
		sdhc2 = "/soc/sdhci@74a4900";
		msmgpio = "/soc/pinctrl@1010000";
		blsp1_spi0_default = "/soc/pinctrl@1010000/blsp1_spi0_default";
		blsp1_spi0_sleep = "/soc/pinctrl@1010000/blsp1_spi0_sleep";
		blsp1_i2c2_default = "/soc/pinctrl@1010000/blsp1_i2c2_default";
		blsp1_i2c2_sleep = "/soc/pinctrl@1010000/blsp1_i2c2_sleep";
		blsp2_i2c0_default = "/soc/pinctrl@1010000/blsp2_i2c0";
		blsp2_i2c0_sleep = "/soc/pinctrl@1010000/blsp2_i2c0_sleep";
		blsp2_uart1_2pins_default = "/soc/pinctrl@1010000/blsp2_uart1_2pins";
		blsp2_uart1_2pins_sleep = "/soc/pinctrl@1010000/blsp2_uart1_2pins_sleep";
		blsp2_uart1_4pins_default = "/soc/pinctrl@1010000/blsp2_uart1_4pins";
		blsp2_uart1_4pins_sleep = "/soc/pinctrl@1010000/blsp2_uart1_4pins_sleep";
		blsp2_i2c1_default = "/soc/pinctrl@1010000/blsp2_i2c1";
		blsp2_i2c1_sleep = "/soc/pinctrl@1010000/blsp2_i2c1_sleep";
		blsp2_uart2_2pins_default = "/soc/pinctrl@1010000/blsp2_uart2_2pins";
		blsp2_uart2_2pins_sleep = "/soc/pinctrl@1010000/blsp2_uart2_2pins_sleep";
		blsp2_uart2_4pins_default = "/soc/pinctrl@1010000/blsp2_uart2_4pins";
		blsp2_uart2_4pins_sleep = "/soc/pinctrl@1010000/blsp2_uart2_4pins_sleep";
		blsp2_spi5_default = "/soc/pinctrl@1010000/blsp2_spi5_default";
		blsp2_spi5_sleep = "/soc/pinctrl@1010000/blsp2_spi5_sleep";
		sdc2_clk_on = "/soc/pinctrl@1010000/sdc2_clk_on";
		sdc2_clk_off = "/soc/pinctrl@1010000/sdc2_clk_off";
		sdc2_cmd_on = "/soc/pinctrl@1010000/sdc2_cmd_on";
		sdc2_cmd_off = "/soc/pinctrl@1010000/sdc2_cmd_off";
		sdc2_data_on = "/soc/pinctrl@1010000/sdc2_data_on";
		sdc2_data_off = "/soc/pinctrl@1010000/sdc2_data_off";
		sdc2_cd_on = "/soc/pinctrl@1010000/sdc2_cd_on";
		sdc2_cd_off = "/soc/pinctrl@1010000/sdc2_cd_off";
		spmi_bus = "/soc/qcom,spmi@400f000";
		pm8994_gpios = "/soc/qcom,spmi@400f000/pmic@0/gpios@c000";
		ls_exp_gpio_f = "/soc/qcom,spmi@400f000/pmic@0/gpios@c000/pm8994_gpio5";
		volume_up_gpio = "/soc/qcom,spmi@400f000/pmic@0/gpios@c000/pm8996_gpio2";
		usb3_vbus_det_gpio = "/soc/qcom,spmi@400f000/pmic@0/gpios@c000/pm8996_gpio22";
		pm8994_mpps = "/soc/qcom,spmi@400f000/pmic@0/mpps@a000";
		pmi8994_gpios = "/soc/qcom,spmi@400f000/pmic@2/gpios@c000";
		usb2_vbus_det_gpio = "/soc/qcom,spmi@400f000/pmic@2/gpios@c000/pmi8996_gpio6";
		mmcc = "/soc/clock-controller@8c0000";
		qusb2p_hstx_trim = "/soc/qfprom@74000/hstx_trim@24e";
		qusb2s_hstx_trim = "/soc/qfprom@74000/hstx_trim@24f";
		pciephy_0 = "/soc/phy@34000/lane@35000";
		pciephy_1 = "/soc/phy@34000/lane@36000";
		pciephy_2 = "/soc/phy@34000/lane@37000";
		ssusb_phy_0 = "/soc/phy@7410000/lane@7410200";
		hsusb_phy1 = "/soc/phy@7411000";
		hsusb_phy2 = "/soc/phy@7412000";
		usb2 = "/soc/usb@7600000";
		usb3 = "/soc/usb@6a00000";
		usb3_id = "/soc/usb3-id";
		usb2_id = "/soc/usb2-id";
		adsp_smp2p_out = "/adsp-smp2p/master-kernel";
		adsp_smp2p_in = "/adsp-smp2p/slave-kernel";
		modem_smp2p_out = "/modem-smp2p/master-kernel";
		modem_smp2p_in = "/modem-smp2p/slave-kernel";
		slpi_smp2p_in = "/smp2p-slpi/slave-kernel";
		slpi_smp2p_out = "/smp2p-slpi/master-kernel";
	};
};
